AUTOSAR XML (schema 00044)
package /E40_Platform_System_SystemPackage/Components
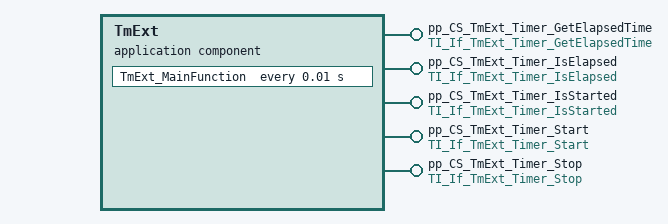
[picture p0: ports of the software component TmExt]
  application sw component type TmExt
    5 x provide port:
      pp_CS_TmExt_Timer_GetElapsedTime: server-com-spec{operation=Timer_GetElapsedTime, queue-length=1}, provided-interface=TI_If_TmExt_Timer_GetElapsedTime
      pp_CS_TmExt_Timer_IsElapsed: server-com-spec{operation=Timer_IsElapsed, queue-length=1}, provided-interface=TI_If_TmExt_Timer_IsElapsed
      pp_CS_TmExt_Timer_IsStarted: server-com-spec{operation=Timer_IsStarted, queue-length=1}, provided-interface=TI_If_TmExt_Timer_IsStarted
      pp_CS_TmExt_Timer_Start: server-com-spec{operation=Timer_Start, queue-length=1}, provided-interface=TI_If_TmExt_Timer_Start
      pp_CS_TmExt_Timer_Stop: server-com-spec{operation=Timer_Stop, queue-length=1}, provided-interface=TI_If_TmExt_Timer_Stop
    behavior IB_TmExt
      timing event TETmExt_MainFunction: start-on-event=TmExt_MainFunction, period=0.01
      5 x operation invoked event:
        OIE_pp_CS_TmExt_Timer_GetElapsedTime_TmExt_Timer_GetElapsedTimeTrigByTimer_GetElapsedTime: start-on-event=TmExt_Timer_GetElapsedTime, operation=pp_CS_TmExt_Timer_GetElapsedTime.Timer_GetElapsedTime
        OIE_pp_CS_TmExt_Timer_IsElapsed_TmExt_Timer_IsElapsedTrigByTimer_IsElapsed: start-on-event=TmExt_Timer_IsElapsed, operation=pp_CS_TmExt_Timer_IsElapsed.Timer_IsElapsed
        OIE_pp_CS_TmExt_Timer_IsStarted_TmExt_Timer_IsStartedTrigByTimer_IsStarted: start-on-event=TmExt_Timer_IsStarted, operation=pp_CS_TmExt_Timer_IsStarted.Timer_IsStarted
        OIE_pp_CS_TmExt_Timer_Start_TmExt_Timer_StartTrigByTimer_Start: start-on-event=TmExt_Timer_Start, operation=pp_CS_TmExt_Timer_Start.Timer_Start
        OIE_pp_CS_TmExt_Timer_Stop_TmExt_Timer_StopTrigByTimer_Stop: start-on-event=TmExt_Timer_Stop, operation=pp_CS_TmExt_Timer_Stop.Timer_Stop
      port-api-options:
        enable-take-address=false, indirect-api=false, port=pp_CS_TmExt_Timer_GetElapsedTime
        enable-take-address=false, indirect-api=false, port=pp_CS_TmExt_Timer_IsElapsed
        enable-take-address=false, indirect-api=false, port=pp_CS_TmExt_Timer_IsStarted
        enable-take-address=false, indirect-api=false, port=pp_CS_TmExt_Timer_Start
        enable-take-address=false, indirect-api=false, port=pp_CS_TmExt_Timer_Stop
      6 x runnable, all with can-be-invoked-concurrently=true:
        TmExt_MainFunction
        TmExt_Timer_GetElapsedTime
        TmExt_Timer_IsElapsed
        TmExt_Timer_IsStarted
        TmExt_Timer_Start
        TmExt_Timer_Stop
  swc implementation IMPL_TmExt: behavior=IB_TmExt
